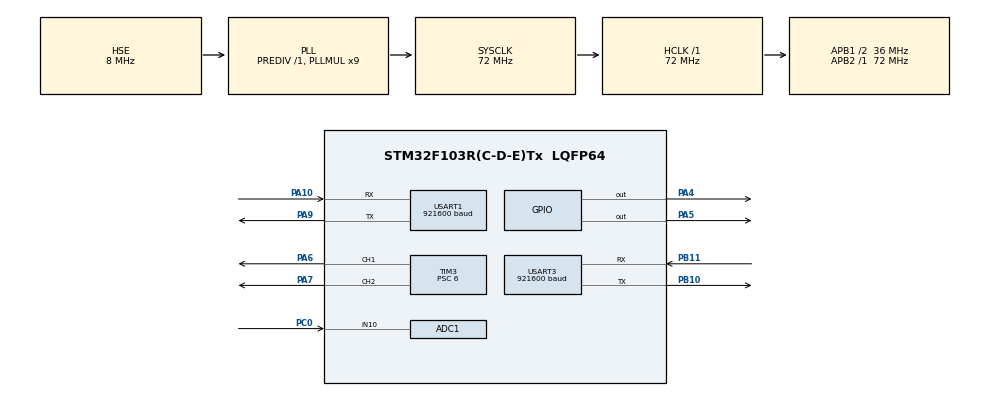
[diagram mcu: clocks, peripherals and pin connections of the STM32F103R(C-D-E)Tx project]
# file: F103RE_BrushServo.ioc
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ADC1.Channel-11\#ChannelRegularConversion=ADC_CHANNEL_10
ADC1.NbrOfConversion=1
ADC1.NbrOfConversionFlag=1
ADC1.Rank-11\#ChannelRegularConversion=1
ADC1.SamplingTime-11\#ChannelRegularConversion=ADC_SAMPLETIME_1CYCLE_5
ADC1.master=1
Dma.ADC1.1.Direction=DMA_PERIPH_TO_MEMORY
Dma.ADC1.1.Instance=DMA1_Channel1
Dma.ADC1.1.MemDataAlignment=DMA_MDATAALIGN_HALFWORD
Dma.ADC1.1.MemInc=DMA_MINC_ENABLE
Dma.ADC1.1.Mode=DMA_NORMAL
Dma.ADC1.1.PeriphDataAlignment=DMA_PDATAALIGN_HALFWORD
Dma.ADC1.1.PeriphInc=DMA_PINC_DISABLE
Dma.ADC1.1.Priority=DMA_PRIORITY_LOW
Dma.Request0=USART1_TX
Dma.Request1=ADC1
Dma.USART1_TX.0.Direction=DMA_MEMORY_TO_PERIPH
Dma.USART1_TX.0.Instance=DMA1_Channel4
Dma.USART1_TX.0.MemDataAlignment=DMA_MDATAALIGN_BYTE
Dma.USART1_TX.0.MemInc=DMA_MINC_ENABLE
Dma.USART1_TX.0.Mode=DMA_NORMAL
Dma.USART1_TX.0.PeriphDataAlignment=DMA_PDATAALIGN_BYTE
Dma.USART1_TX.0.PeriphInc=DMA_PINC_DISABLE
Dma.USART1_TX.0.Priority=DMA_PRIORITY_LOW
Mcu.Family=STM32F1
Mcu.Name=STM32F103R(C-D-E)Tx
Mcu.Package=LQFP64
NVIC.DMA1_Channel1_IRQn=true\:0\:0\:false\:false\:true\:false\:true\:true
NVIC.DMA1_Channel4_IRQn=true\:0\:0\:false\:false\:true\:false\:true\:true
NVIC.PriorityGroup=NVIC_PRIORITYGROUP_4
NVIC.TIM3_IRQn=true\:0\:0\:false\:false\:true\:true\:true\:true
NVIC.TIM6_IRQn=true\:0\:0\:false\:false\:true\:true\:true\:true
NVIC.USART1_IRQn=true\:0\:0\:false\:false\:true\:true\:true\:true
PA10.Mode=Asynchronous
PA10.Signal=USART1_RX
PA13.Mode=Serial_Wire
PA13.Signal=SYS_JTMS-SWDIO
PA14.Mode=Serial_Wire
PA14.Signal=SYS_JTCK-SWCLK
PA4.GPIO_Speed=GPIO_SPEED_FREQ_LOW
PA4.PinState=GPIO_PIN_RESET
PA4.Signal=GPIO_Output
PA5.GPIO_Speed=GPIO_SPEED_FREQ_LOW
PA5.Signal=GPIO_Output
PA6.Signal=S_TIM3_CH1
PA7.Signal=S_TIM3_CH2
PA9.Mode=Asynchronous
PA9.Signal=USART1_TX
PB10.Mode=Asynchronous
PB10.Signal=USART3_TX
PB11.Mode=Asynchronous
PB11.Signal=USART3_RX
PC0.Signal=ADCx_IN10
PC14-OSC32_IN.Mode=LSE-External-Oscillator
PC14-OSC32_IN.Signal=RCC_OSC32_IN
PC15-OSC32_OUT.Mode=LSE-External-Oscillator
PC15-OSC32_OUT.Signal=RCC_OSC32_OUT
PD0-OSC_IN.Mode=HSE-External-Oscillator
PD0-OSC_IN.Signal=RCC_OSC_IN
PD1-OSC_OUT.Mode=HSE-External-Oscillator
PD1-OSC_OUT.Signal=RCC_OSC_OUT
ProjectManager.HeapSize=0x200
ProjectManager.StackSize=0x400
ProjectManager.TargetToolchain=STM32CubeIDE
RCC.ADCPresc=RCC_ADCPCLK2_DIV6
RCC.AHBFreq_Value=72000000
RCC.APB1CLKDivider=RCC_HCLK_DIV2
RCC.APB1Freq_Value=36000000
RCC.APB1TimFreq_Value=72000000
RCC.APB2Freq_Value=72000000
RCC.APB2TimFreq_Value=72000000
RCC.HCLKFreq_Value=72000000
RCC.PLLMUL=RCC_PLL_MUL9
RCC.PLLSourceVirtual=RCC_PLLSOURCE_HSE
RCC.SYSCLKFreq_VALUE=72000000
RCC.SYSCLKSource=RCC_SYSCLKSOURCE_PLLCLK
RCC.USBFreq_Value=72000000
SH.ADCx_IN10.0=ADC1_IN10,IN10
SH.S_TIM3_CH1.0=TIM3_CH1,PWM Generation1 CH1
SH.S_TIM3_CH2.0=TIM3_CH2,PWM Generation2 CH2
TIM3.Channel-PWM\ Generation1\ CH1=TIM_CHANNEL_1
TIM3.Channel-PWM\ Generation2\ CH2=TIM_CHANNEL_2
TIM3.Period=2047
TIM3.Prescaler=6
TIM6.Period=999
TIM6.Prescaler=71
USART1.BaudRate=921600
USART1.VirtualMode=VM_ASYNC
USART3.BaudRate=921600
USART3.VirtualMode=VM_ASYNC
VP_TIM6_VS_ClockSourceINT.Mode=Enable_Timer
board=custom

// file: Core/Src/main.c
/* USER CODE BEGIN Header */
/**
  ******************************************************************************
  * @file           : main.c
  * @brief          : Main program body
  ******************************************************************************
  * @attention
  *
  * Copyright (c) 2022 STMicroelectronics.
  * All rights reserved.
  *
  * This software is licensed under terms that can be found in the LICENSE file
  * in the root directory of this software component.
  * If no LICENSE file comes with this software, it is provided AS-IS.
  *
  ******************************************************************************
  */
/* USER CODE END Header */
#include "main.h"

/* USER CODE BEGIN Includes */
#include "Cpp/Start.hpp"
/* USER CODE END Includes */

ADC_HandleTypeDef hadc1;
DMA_HandleTypeDef hdma_adc1;

TIM_HandleTypeDef htim3;
TIM_HandleTypeDef htim6;

UART_HandleTypeDef huart1;
UART_HandleTypeDef huart3;
DMA_HandleTypeDef hdma_usart1_tx;

void SystemClock_Config(void);
static void MX_GPIO_Init(void);
static void MX_DMA_Init(void);
static void MX_TIM3_Init(void);
static void MX_TIM6_Init(void);
static void MX_ADC1_Init(void);
static void MX_USART1_UART_Init(void);
static void MX_USART3_UART_Init(void);

int main(void)
{

  /* MCU Configuration--------------------------------------------------------*/

  /* Reset of all peripherals, Initializes the Flash interface and the Systick. */
  HAL_Init();

  /* Configure the system clock */
  SystemClock_Config();

  /* Initialize all configured peripherals */
  MX_GPIO_Init();
  MX_DMA_Init();
  MX_TIM3_Init();
  MX_TIM6_Init();
  MX_ADC1_Init();
  MX_USART1_UART_Init();
  MX_USART3_UART_Init();
  /* USER CODE BEGIN 2 */
  HAL_TIM_Base_Start(&htim3);
  HAL_TIM_Base_Start_IT(&htim6);
  HAL_TIM_PWM_Start(&htim3, TIM_CHANNEL_1);
  HAL_TIM_PWM_Start(&htim3, TIM_CHANNEL_2);
  Start();
  /* USER CODE END 2 */

  /* Infinite loop */
  while (1)
  {

  }
}

void SystemClock_Config(void)
{
  RCC_OscInitTypeDef RCC_OscInitStruct = {0};
  RCC_ClkInitTypeDef RCC_ClkInitStruct = {0};
  RCC_PeriphCLKInitTypeDef PeriphClkInit = {0};

  /** Initializes the RCC Oscillators according to the specified parameters
  * in the RCC_OscInitTypeDef structure.
  */
  RCC_OscInitStruct.OscillatorType = RCC_OSCILLATORTYPE_HSE;
  RCC_OscInitStruct.HSEState = RCC_HSE_ON;
  RCC_OscInitStruct.HSEPredivValue = RCC_HSE_PREDIV_DIV1;
  RCC_OscInitStruct.HSIState = RCC_HSI_ON;
  RCC_OscInitStruct.PLL.PLLState = RCC_PLL_ON;
  RCC_OscInitStruct.PLL.PLLSource = RCC_PLLSOURCE_HSE;
  RCC_OscInitStruct.PLL.PLLMUL = RCC_PLL_MUL9;
  if (HAL_RCC_OscConfig(&RCC_OscInitStruct) != HAL_OK)
  {
    Error_Handler();
  }

  /** Initializes the CPU, AHB and APB buses clocks
  */
  RCC_ClkInitStruct.ClockType = RCC_CLOCKTYPE_HCLK|RCC_CLOCKTYPE_SYSCLK
                              |RCC_CLOCKTYPE_PCLK1|RCC_CLOCKTYPE_PCLK2;
  RCC_ClkInitStruct.SYSCLKSource = RCC_SYSCLKSOURCE_PLLCLK;
  RCC_ClkInitStruct.AHBCLKDivider = RCC_SYSCLK_DIV1;
  RCC_ClkInitStruct.APB1CLKDivider = RCC_HCLK_DIV2;
  RCC_ClkInitStruct.APB2CLKDivider = RCC_HCLK_DIV1;

  if (HAL_RCC_ClockConfig(&RCC_ClkInitStruct, FLASH_LATENCY_2) != HAL_OK)
  {
    Error_Handler();
  }
  PeriphClkInit.PeriphClockSelection = RCC_PERIPHCLK_ADC;
  PeriphClkInit.AdcClockSelection = RCC_ADCPCLK2_DIV6;
  if (HAL_RCCEx_PeriphCLKConfig(&PeriphClkInit) != HAL_OK)
  {
    Error_Handler();
  }
}

static void MX_ADC1_Init(void)
{

  ADC_ChannelConfTypeDef sConfig = {0};

  /** Common config
  */
  hadc1.Instance = ADC1;
  hadc1.Init.ScanConvMode = ADC_SCAN_DISABLE;
  hadc1.Init.ContinuousConvMode = DISABLE;
  hadc1.Init.DiscontinuousConvMode = DISABLE;
  hadc1.Init.ExternalTrigConv = ADC_SOFTWARE_START;
  hadc1.Init.DataAlign = ADC_DATAALIGN_RIGHT;
  hadc1.Init.NbrOfConversion = 1;
  if (HAL_ADC_Init(&hadc1) != HAL_OK)
  {
    Error_Handler();
  }

  /** Configure Regular Channel
  */
  sConfig.Channel = ADC_CHANNEL_10;
  sConfig.Rank = ADC_REGULAR_RANK_1;
  sConfig.SamplingTime = ADC_SAMPLETIME_1CYCLE_5;
  if (HAL_ADC_ConfigChannel(&hadc1, &sConfig) != HAL_OK)
  {
    Error_Handler();
  }

}

static void MX_TIM3_Init(void)
{

  TIM_MasterConfigTypeDef sMasterConfig = {0};
  TIM_OC_InitTypeDef sConfigOC = {0};

  htim3.Instance = TIM3;
  htim3.Init.Prescaler = 6;
  htim3.Init.CounterMode = TIM_COUNTERMODE_UP;
  htim3.Init.Period = 2047;
  htim3.Init.ClockDivision = TIM_CLOCKDIVISION_DIV1;
  htim3.Init.AutoReloadPreload = TIM_AUTORELOAD_PRELOAD_DISABLE;
  if (HAL_TIM_PWM_Init(&htim3) != HAL_OK)
  {
    Error_Handler();
  }
  sMasterConfig.MasterOutputTrigger = TIM_TRGO_RESET;
  sMasterConfig.MasterSlaveMode = TIM_MASTERSLAVEMODE_DISABLE;
  if (HAL_TIMEx_MasterConfigSynchronization(&htim3, &sMasterConfig) != HAL_OK)
  {
    Error_Handler();
  }
  sConfigOC.OCMode = TIM_OCMODE_PWM1;
  sConfigOC.Pulse = 0;
  sConfigOC.OCPolarity = TIM_OCPOLARITY_HIGH;
  sConfigOC.OCFastMode = TIM_OCFAST_DISABLE;
  if (HAL_TIM_PWM_ConfigChannel(&htim3, &sConfigOC, TIM_CHANNEL_1) != HAL_OK)
  {
    Error_Handler();
  }
  if (HAL_TIM_PWM_ConfigChannel(&htim3, &sConfigOC, TIM_CHANNEL_2) != HAL_OK)
  {
    Error_Handler();
  }
  HAL_TIM_MspPostInit(&htim3);

}

static void MX_TIM6_Init(void)
{

  TIM_MasterConfigTypeDef sMasterConfig = {0};

  htim6.Instance = TIM6;
  htim6.Init.Prescaler = 71;
  htim6.Init.CounterMode = TIM_COUNTERMODE_UP;
  htim6.Init.Period = 999;
  htim6.Init.AutoReloadPreload = TIM_AUTORELOAD_PRELOAD_DISABLE;
  if (HAL_TIM_Base_Init(&htim6) != HAL_OK)
  {
    Error_Handler();
  }
  sMasterConfig.MasterOutputTrigger = TIM_TRGO_RESET;
  sMasterConfig.MasterSlaveMode = TIM_MASTERSLAVEMODE_DISABLE;
  if (HAL_TIMEx_MasterConfigSynchronization(&htim6, &sMasterConfig) != HAL_OK)
  {
    Error_Handler();
  }

}

static void MX_USART1_UART_Init(void)
{

  huart1.Instance = USART1;
  huart1.Init.BaudRate = 921600;
  huart1.Init.WordLength = UART_WORDLENGTH_8B;
  huart1.Init.StopBits = UART_STOPBITS_1;
  huart1.Init.Parity = UART_PARITY_NONE;
  huart1.Init.Mode = UART_MODE_TX_RX;
  huart1.Init.HwFlowCtl = UART_HWCONTROL_NONE;
  huart1.Init.OverSampling = UART_OVERSAMPLING_16;
  if (HAL_UART_Init(&huart1) != HAL_OK)
  {
    Error_Handler();
  }

}

static void MX_USART3_UART_Init(void)
{

  huart3.Instance = USART3;
  huart3.Init.BaudRate = 921600;
  huart3.Init.WordLength = UART_WORDLENGTH_8B;
  huart3.Init.StopBits = UART_STOPBITS_1;
  huart3.Init.Parity = UART_PARITY_NONE;
  huart3.Init.Mode = UART_MODE_TX_RX;
  huart3.Init.HwFlowCtl = UART_HWCONTROL_NONE;
  huart3.Init.OverSampling = UART_OVERSAMPLING_16;
  if (HAL_UART_Init(&huart3) != HAL_OK)
  {
    Error_Handler();
  }

}

static void MX_DMA_Init(void)
{

  /* DMA controller clock enable */
  __HAL_RCC_DMA1_CLK_ENABLE();

  /* DMA interrupt init */
  /* DMA1_Channel1_IRQn interrupt configuration */
  HAL_NVIC_SetPriority(DMA1_Channel1_IRQn, 0, 0);
  HAL_NVIC_EnableIRQ(DMA1_Channel1_IRQn);
  /* DMA1_Channel4_IRQn interrupt configuration */
  HAL_NVIC_SetPriority(DMA1_Channel4_IRQn, 0, 0);
  HAL_NVIC_EnableIRQ(DMA1_Channel4_IRQn);

}

static void MX_GPIO_Init(void)
{
  GPIO_InitTypeDef GPIO_InitStruct = {0};

  /* GPIO Ports Clock Enable */
  __HAL_RCC_GPIOC_CLK_ENABLE();
  __HAL_RCC_GPIOD_CLK_ENABLE();
  __HAL_RCC_GPIOA_CLK_ENABLE();
  __HAL_RCC_GPIOB_CLK_ENABLE();

  /*Configure GPIO pin Output Level */
  HAL_GPIO_WritePin(GPIOA, GPIO_PIN_4|GPIO_PIN_5, GPIO_PIN_RESET);

  /*Configure GPIO pins : PA4 PA5 */
  GPIO_InitStruct.Pin = GPIO_PIN_4|GPIO_PIN_5;
  GPIO_InitStruct.Mode = GPIO_MODE_OUTPUT_PP;
  GPIO_InitStruct.Pull = GPIO_NOPULL;
  GPIO_InitStruct.Speed = GPIO_SPEED_FREQ_LOW;
  HAL_GPIO_Init(GPIOA, &GPIO_InitStruct);

}

void Error_Handler(void)
{
  __disable_irq();
  while (1)
  {
  }
}
